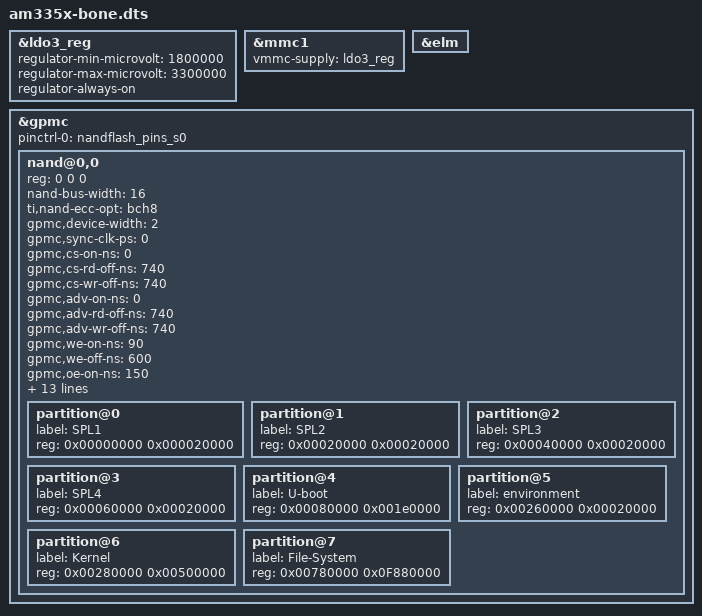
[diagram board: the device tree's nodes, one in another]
/*
 * Copyright (C) 2012 Texas Instruments Incorporated - http://www.ti.com/
 *
 * This program is free software; you can redistribute it and/or modify
 * it under the terms of the GNU General Public License version 2 as
 * published by the Free Software Foundation.
 */
/dts-v1/;

#include "am33xx.dtsi"
#include "am335x-bone-common.dtsi"

&ldo3_reg {
	regulator-min-microvolt = <1800000>;
	regulator-max-microvolt = <3300000>;
	regulator-always-on;
};

&mmc1 {
	vmmc-supply = <&ldo3_reg>;
};

&elm {
	status = "okay";
};

&gpmc {
	status = "okay";
	pinctrl-names = "default";
	pinctrl-0 = <&nandflash_pins_s0>;
	ranges = <0 0 0x08000000 0x10000000>;	/* CS0: NAND */
	nand@0,0 {
		reg = <0 0 0>; /* CS0, offset 0 */
		nand-bus-width = <16>;
		ti,nand-ecc-opt = "bch8";
		gpmc,device-width = <2>;
		gpmc,sync-clk-ps = <0>;
		gpmc,cs-on-ns = <0>;
		gpmc,cs-rd-off-ns = <740>;
		gpmc,cs-wr-off-ns = <740>;
		gpmc,adv-on-ns = <0>;
		gpmc,adv-rd-off-ns = <740>;
		gpmc,adv-wr-off-ns = <740>;
		gpmc,we-on-ns = <90>;
		gpmc,we-off-ns = <600>;
		gpmc,oe-on-ns = <150>;
		gpmc,oe-off-ns = <650>;
		gpmc,access-ns = <560>;
		gpmc,rd-cycle-ns = <740>;
		gpmc,wr-cycle-ns = <740>;
		gpmc,wait-on-read = "true";
		gpmc,wait-on-write = "true";
		gpmc,bus-turnaround-ns = <0>;
		gpmc,cycle2cycle-delay-ns = <0>;
		gpmc,clk-activation-ns = <0>;
		gpmc,wait-monitoring-ns = <0>;
		gpmc,wr-access-ns = <40>;
		gpmc,wr-data-mux-bus-ns = <0>;
		#address-cells = <1>;
		#size-cells = <1>;
		ti,elm-id = <&elm>;
		/* MTD partition table */
		partition@0 {
			label = "SPL1";
			reg = <0x00000000 0x000020000>;
		};
		partition@1 {
			label = "SPL2";
			reg = <0x00020000 0x00020000>;
		};
		partition@2 {
			label = "SPL3";
			reg = <0x00040000 0x00020000>;
		};
		partition@3 {
			label = "SPL4";
			reg = <0x00060000 0x00020000>;
		};
		partition@4 {
			label = "U-boot";
			reg = <0x00080000 0x001e0000>;
		};
		partition@5 {
			label = "environment";
			reg = <0x00260000 0x00020000>;
		};
		partition@6 {
			label = "Kernel";
			reg = <0x00280000 0x00500000>;
		};
		partition@7 {
			label = "File-System";
			reg = <0x00780000 0x0F880000>;
		};
	};
};
